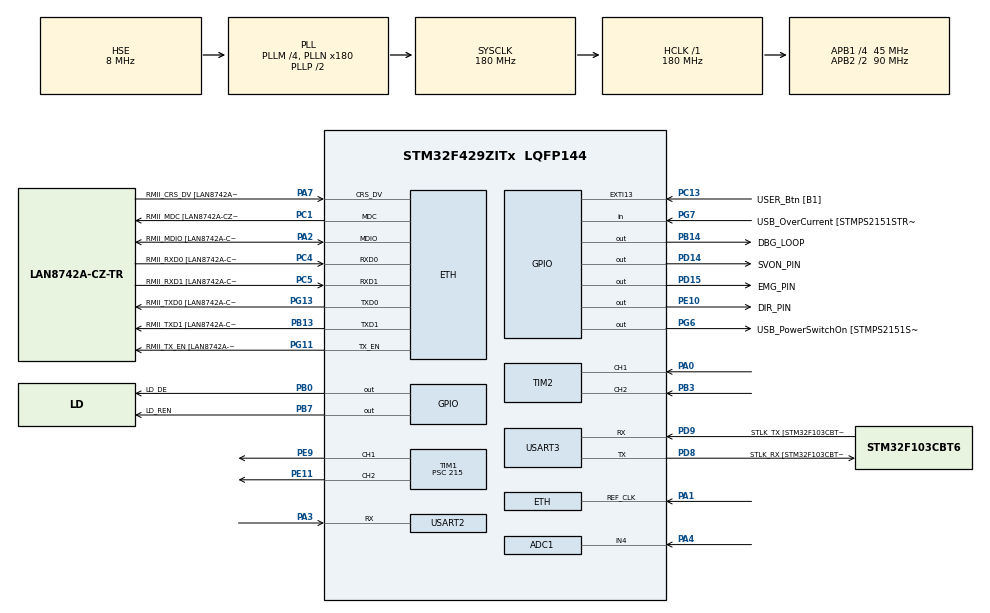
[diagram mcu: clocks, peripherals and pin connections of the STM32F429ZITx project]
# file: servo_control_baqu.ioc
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ADC1.Channel-0\#ChannelRegularConversion=ADC_CHANNEL_4
ADC1.NbrOfConversionFlag=1
ADC1.Rank-0\#ChannelRegularConversion=1
ADC1.SamplingTime-0\#ChannelRegularConversion=ADC_SAMPLETIME_3CYCLES
ADC1.master=1
ETH.MediaInterface=HAL_ETH_RMII_MODE
ETH.RxMode=ETH_RXPOLLING_MODE
IWDG.Prescaler=IWDG_PRESCALER_256
LWIP.BSP.number=1
LWIP.GATEWAY_ADDRESS=010.177.021.001
LWIP.IP_ADDRESS=010.177.021.004
LWIP.LWIP_DHCP=0
LWIP.LWIP_TCP=0
LWIP.MEM_SIZE=8192
LWIP.NETMASK_ADDRESS=255.255.255.000
LWIP.PBUF_POOL_BUFSIZE=1524
LWIP.Version=v2.1.2_Cube
LWIP0.BSP.STBoard=false
LWIP0.BSP.api=BSP_COMPONENT_DRIVER
LWIP0.BSP.component=LAN8742
LWIP0.BSP.instance=LAN8742
LWIP0.BSP.name=Driver_PHY
LWIP0.BSP.semaphore=S_LAN8742
LWIP0.BSP.solution=LAN8742
Mcu.Family=STM32F4
Mcu.Name=STM32F429ZITx
Mcu.Package=LQFP144
NVIC.ETH_IRQn=true\:5\:0\:true\:false\:true\:true\:true\:true
NVIC.PriorityGroup=NVIC_PRIORITYGROUP_4
NVIC.TIM1_CC_IRQn=true\:1\:0\:true\:false\:true\:true\:true\:true
PA0/WKUP.Signal=S_TIM2_CH1_ETR
PA1.Mode=RMII
PA1.Signal=ETH_REF_CLK
PA11.GPIO_Label=USB_DM
PA11.Signal=USB_OTG_FS_DM
PA12.GPIO_Label=USB_DP
PA12.Signal=USB_OTG_FS_DP
PA13.GPIO_Label=TMS
PA13.Mode=Serial_Wire
PA13.Signal=SYS_JTMS-SWDIO
PA14.GPIO_Label=TCK
PA14.Mode=Serial_Wire
PA14.Signal=SYS_JTCK-SWCLK
PA2.GPIO_Label=RMII_MDIO [LAN8742A-CZ-TR_MDIO]
PA2.Mode=RMII
PA2.Signal=ETH_MDIO
PA3.Mode=Asynchronous
PA3.Signal=USART2_RX
PA4.Signal=ADCx_IN4
PA7.GPIO_Label=RMII_CRS_DV [LAN8742A-CZ-TR_CRS_DV]
PA7.Mode=RMII
PA7.Signal=ETH_CRS_DV
PA8.GPIO_Label=USB_SOF [TP1]
PA8.Signal=USB_OTG_FS_SOF
PB0.GPIO_Label=LD_DE
PB0.PinState=GPIO_PIN_SET
PB0.Signal=GPIO_Output
PB13.GPIO_Label=RMII_TXD1 [LAN8742A-CZ-TR_TXD1]
PB13.Mode=RMII
PB13.Signal=ETH_TXD1
PB14.GPIO_Label=DBG_LOOP
PB14.Signal=GPIO_Output
PB3.Signal=S_TIM2_CH2
PB7.GPIO_Label=LD_REN
PB7.PinState=GPIO_PIN_SET
PB7.Signal=GPIO_Output
PC1.GPIO_Label=RMII_MDC [LAN8742A-CZ-TR_MDC]
PC1.Mode=RMII
PC1.Signal=ETH_MDC
PC13.GPIO_Label=USER_Btn [B1]
PC13.Signal=GPXTI13
PC14/OSC32_IN.Mode=LSE-External-Oscillator
PC14/OSC32_IN.Signal=RCC_OSC32_IN
PC15/OSC32_OUT.Mode=LSE-External-Oscillator
PC15/OSC32_OUT.Signal=RCC_OSC32_OUT
PC4.GPIO_Label=RMII_RXD0 [LAN8742A-CZ-TR_RXD0]
PC4.Mode=RMII
PC4.Signal=ETH_RXD0
PC5.GPIO_Label=RMII_RXD1 [LAN8742A-CZ-TR_RXD1]
PC5.Mode=RMII
PC5.Signal=ETH_RXD1
PD14.GPIO_Label=SVON_PIN
PD14.PinState=GPIO_PIN_SET
PD14.Signal=GPIO_Output
PD15.GPIO_Label=EMG_PIN
PD15.PinState=GPIO_PIN_SET
PD15.Signal=GPIO_Output
PD8.GPIO_Label=STLK_RX [STM32F103CBT6_PA3]
PD8.Mode=Asynchronous
PD8.Signal=USART3_TX
PD9.GPIO_Label=STLK_TX [STM32F103CBT6_PA2]
PD9.Mode=Asynchronous
PD9.Signal=USART3_RX
PE10.GPIO_Label=DIR_PIN
PE10.Signal=GPIO_Output
PE11.Signal=S_TIM1_CH2
PE9.Signal=S_TIM1_CH1
PG11.GPIO_Label=RMII_TX_EN [LAN8742A-CZ-TR_TXEN]
PG11.Mode=RMII
PG11.Signal=ETH_TX_EN
PG13.GPIO_Label=RMII_TXD0 [LAN8742A-CZ-TR_TXD0]
PG13.Mode=RMII
PG13.Signal=ETH_TXD0
PG6.GPIO_Label=USB_PowerSwitchOn [STMPS2151STR_EN]
PG6.Signal=GPIO_Output
PG7.GPIO_Label=USB_OverCurrent [STMPS2151STR_FAULT]
PG7.Signal=GPIO_Input
PH0/OSC_IN.GPIO_Label=MCO [STM32F103CBT6_PA8]
PH0/OSC_IN.Mode=HSE-External-Clock-Source
PH0/OSC_IN.Signal=RCC_OSC_IN
PH1/OSC_OUT.Mode=HSE-External-Clock-Source
PH1/OSC_OUT.Signal=RCC_OSC_OUT
ProjectManager.HeapSize=0x2000
ProjectManager.StackSize=0x1000
ProjectManager.TargetToolchain=STM32CubeIDE
RCC.48MHZClocksFreq_Value=51428571.428571425
RCC.AHBFreq_Value=180000000
RCC.APB1CLKDivider=RCC_HCLK_DIV4
RCC.APB1Freq_Value=45000000
RCC.APB1TimFreq_Value=90000000
RCC.APB2CLKDivider=RCC_HCLK_DIV2
RCC.APB2Freq_Value=90000000
RCC.APB2TimFreq_Value=180000000
RCC.CortexFreq_Value=180000000
RCC.HCLKFreq_Value=180000000
RCC.HSE_VALUE=8000000
RCC.HSI_VALUE=16000000
RCC.PLLM=4
RCC.PLLMUL=RCC_PLL_MUL9
RCC.PLLN=180
RCC.PLLQ=7
RCC.PLLSourceVirtual=RCC_PLLSOURCE_HSE
RCC.PRESCALERUSB=RCC_USBCLKSOURCE_PLL_DIV1_5
RCC.SYSCLKFreq_VALUE=180000000
RCC.SYSCLKSource=RCC_SYSCLKSOURCE_PLLCLK
RCC.SYSCLKSourceVirtual=RCC_SYSCLKSOURCE_PLLCLK
RCC.USBFreq_Value=48000000
RCC.VCOOutputFreq_Value=360000000
SH.ADCx_IN4.0=ADC1_IN4,IN4
SH.S_TIM1_CH1.0=TIM1_CH1,PWM Generation1 CH1
SH.S_TIM1_CH2.0=TIM1_CH2,PWM Generation2 CH2
SH.S_TIM2_CH1_ETR.0=TIM2_CH1,Encoder_Interface
SH.S_TIM2_CH2.0=TIM2_CH2,Encoder_Interface
TIM1.Channel-PWM\ Generation1\ CH1=TIM_CHANNEL_1
TIM1.Channel-PWM\ Generation2\ CH2=TIM_CHANNEL_2
TIM1.OC1Preload_PWM=DISABLE
TIM1.OC2Preload_PWM=DISABLE
TIM1.Period=9
TIM1.Prescaler=215
TIM1.Pulse-PWM\ Generation1\ CH1=5
TIM1.Pulse-PWM\ Generation2\ CH2=5
TIM2.EncoderMode=TIM_ENCODERMODE_TI12
USART2.VirtualMode=VM_ASYNC
USART3.VirtualMode=VM_ASYNC
VP_IWDG_VS_IWDG.Mode=IWDG_Activate
VP_LWIP_VS_Enabled.Mode=Enabled
VP_TIM1_VS_ClockSourceINT.Mode=Internal
board=NUCLEO-F429ZI

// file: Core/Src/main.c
/* USER CODE BEGIN Header */
/**
  ******************************************************************************
  * @file           : main.c
  * @brief          : Main program body
  ******************************************************************************
  * @attention
  *
  * Copyright (c) 2026 STMicroelectronics.
  * All rights reserved.
  *
  * This software is licensed under terms that can be found in the LICENSE file
  * in the root directory of this software component.
  * If no LICENSE file comes with this software, it is provided AS-IS.
  *
  ******************************************************************************
  */
/* USER CODE END Header */
#include "main.h"
#include "adc.h"
#include "iwdg.h"
#include "lwip.h"
#include "tim.h"
#include "usart.h"
#include "gpio.h"

/* USER CODE BEGIN Includes */
#include "app_runtime.h"
/* USER CODE END Includes */

void SystemClock_Config(void);

int main(void)
{

  /* MCU Configuration--------------------------------------------------------*/

  /* Reset of all peripherals, Initializes the Flash interface and the Systick. */
  HAL_Init();

  /* Configure the system clock */
  SystemClock_Config();

  /* Initialize all configured peripherals */
  MX_GPIO_Init();
  MX_USART3_UART_Init();
  MX_ADC1_Init();
  MX_TIM1_Init();
  MX_IWDG_Init();
  MX_LWIP_Init();
  MX_TIM2_Init();
  MX_USART2_UART_Init();
  /* USER CODE BEGIN 2 */
  AppRuntime_Init();
  /* USER CODE END 2 */

  /* Infinite loop */
  while (1)
  {

    /* USER CODE BEGIN 3 */
    AppRuntime_RunIteration();
  }
  /* USER CODE END 3 */
}

void SystemClock_Config(void)
{
  RCC_OscInitTypeDef RCC_OscInitStruct = {0};
  RCC_ClkInitTypeDef RCC_ClkInitStruct = {0};

  /** Configure the main internal regulator output voltage
  */
  __HAL_RCC_PWR_CLK_ENABLE();
  __HAL_PWR_VOLTAGESCALING_CONFIG(PWR_REGULATOR_VOLTAGE_SCALE1);

  /** Initializes the RCC Oscillators according to the specified parameters
  * in the RCC_OscInitTypeDef structure.
  */
  RCC_OscInitStruct.OscillatorType = RCC_OSCILLATORTYPE_LSI|RCC_OSCILLATORTYPE_HSE;
  RCC_OscInitStruct.HSEState = RCC_HSE_BYPASS;
  RCC_OscInitStruct.LSIState = RCC_LSI_ON;
  RCC_OscInitStruct.PLL.PLLState = RCC_PLL_ON;
  RCC_OscInitStruct.PLL.PLLSource = RCC_PLLSOURCE_HSE;
  RCC_OscInitStruct.PLL.PLLM = 4;
  RCC_OscInitStruct.PLL.PLLN = 180;
  RCC_OscInitStruct.PLL.PLLP = RCC_PLLP_DIV2;
  RCC_OscInitStruct.PLL.PLLQ = 7;
  if (HAL_RCC_OscConfig(&RCC_OscInitStruct) != HAL_OK)
  {
    Error_Handler();
  }

  /** Activate the Over-Drive mode
  */
  if (HAL_PWREx_EnableOverDrive() != HAL_OK)
  {
    Error_Handler();
  }

  /** Initializes the CPU, AHB and APB buses clocks
  */
  RCC_ClkInitStruct.ClockType = RCC_CLOCKTYPE_HCLK|RCC_CLOCKTYPE_SYSCLK
                              |RCC_CLOCKTYPE_PCLK1|RCC_CLOCKTYPE_PCLK2;
  RCC_ClkInitStruct.SYSCLKSource = RCC_SYSCLKSOURCE_PLLCLK;
  RCC_ClkInitStruct.AHBCLKDivider = RCC_SYSCLK_DIV1;
  RCC_ClkInitStruct.APB1CLKDivider = RCC_HCLK_DIV4;
  RCC_ClkInitStruct.APB2CLKDivider = RCC_HCLK_DIV2;

  if (HAL_RCC_ClockConfig(&RCC_ClkInitStruct, FLASH_LATENCY_5) != HAL_OK)
  {
    Error_Handler();
  }
}

/* USER CODE BEGIN 4 */

// printf UART 리다?�렉??
int __io_putchar(int ch)
{
    HAL_UART_Transmit(&huart3, (uint8_t *)&ch, 1, HAL_MAX_DELAY);
    return ch;
}

/* USER CODE END 4 */

void Error_Handler(void)
{
  __disable_irq();
  while (1)
  {
  }
}
